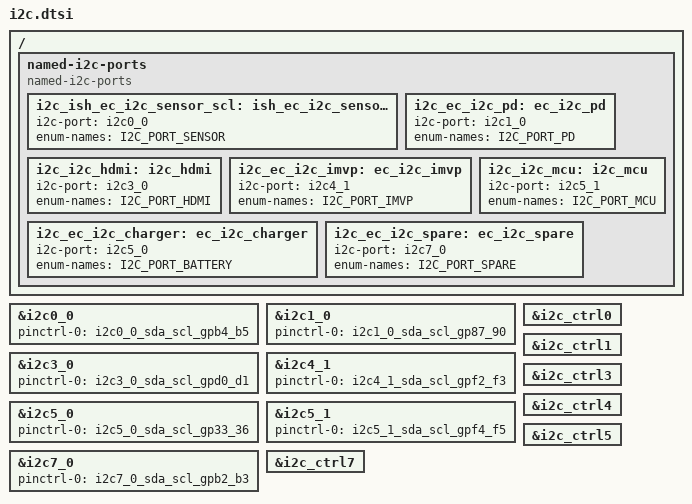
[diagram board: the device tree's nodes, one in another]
/* Copyright 2025 The ChromiumOS Authors
 * Use of this source code is governed by a BSD-style license that can be
 * found in the LICENSE file.
 */

/ {
	named-i2c-ports {
		compatible = "named-i2c-ports";

		i2c_ish_ec_i2c_sensor_scl: ish_ec_i2c_sensor_scl {
			i2c-port = <&i2c0_0>;
			enum-names = "I2C_PORT_SENSOR";
		};
		i2c_ec_i2c_pd: ec_i2c_pd {
			i2c-port = <&i2c1_0>;
			enum-names = "I2C_PORT_PD";
		};
		i2c_i2c_hdmi: i2c_hdmi {
			i2c-port = <&i2c3_0>;
			enum-names = "I2C_PORT_HDMI";
		};
		i2c_ec_i2c_imvp: ec_i2c_imvp {
			i2c-port = <&i2c4_1>;
			enum-names = "I2C_PORT_IMVP";
		};
		i2c_ec_i2c_charger: ec_i2c_charger {
			i2c-port = <&i2c5_0>;
			enum-names = "I2C_PORT_CHARGER";
			enum-names = "I2C_PORT_BATTERY";
		};
		i2c_i2c_mcu: i2c_mcu {
			i2c-port = <&i2c5_1>;
			enum-names = "I2C_PORT_MCU";
		};
		i2c_ec_i2c_spare: ec_i2c_spare{
			i2c-port = <&i2c7_0>;
			enum-names = "I2C_PORT_SPARE";
		};
	};
};

&i2c0_0 {
	status = "okay";
	pinctrl-0 = <&i2c0_0_sda_scl_gpb4_b5>;
	pinctrl-names = "default";
};

&i2c1_0 {
	status = "okay";
	pinctrl-0 = <&i2c1_0_sda_scl_gp87_90>;
	pinctrl-names = "default";
};

&i2c3_0 {
	status = "okay";
	pinctrl-0 = <&i2c3_0_sda_scl_gpd0_d1>;
	pinctrl-names = "default";
};

&i2c4_1 {
	status = "okay";
	pinctrl-0 = <&i2c4_1_sda_scl_gpf2_f3>;
	pinctrl-names = "default";
};

&i2c5_0 {
	status = "okay";
	pinctrl-0 = <&i2c5_0_sda_scl_gp33_36>;
	pinctrl-names = "default";
};

&i2c5_1 {
	status = "okay";
	pinctrl-0 = <&i2c5_1_sda_scl_gpf4_f5>;
	pinctrl-names = "default";
};

&i2c7_0 {
	status = "okay";
	pinctrl-0 = <&i2c7_0_sda_scl_gpb2_b3>;
	pinctrl-names = "default";
};

&i2c_ctrl0 {
	status = "okay";
};

&i2c_ctrl1 {
	status = "okay";
};

&i2c_ctrl3 {
	status = "okay";
};

&i2c_ctrl4 {
	status = "okay";
};

&i2c_ctrl5 {
	status = "okay";
};

&i2c_ctrl7 {
	status = "okay";
};
